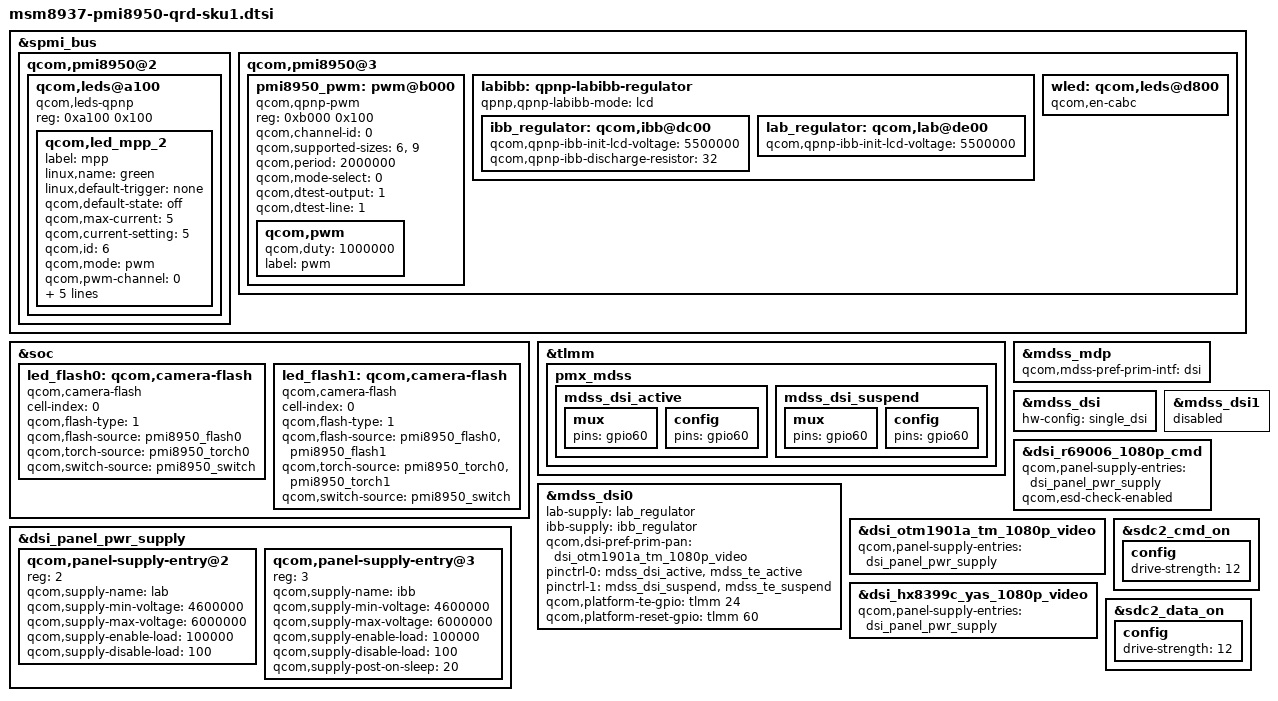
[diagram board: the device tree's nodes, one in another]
/*
 * Copyright (c) 2015-2016, The Linux Foundation. All rights reserved.
 *
 * This program is free software; you can redistribute it and/or modify
 * it under the terms of the GNU General Public License version 2 and
 * only version 2 as published by the Free Software Foundation.
 *
 * This program is distributed in the hope that it will be useful,
 * but WITHOUT ANY WARRANTY; without even the implied warranty of
 * MERCHANTABILITY or FITNESS FOR A PARTICULAR PURPOSE.  See the
 * GNU General Public License for more details.
 */

#include "msm-pmi8950.dtsi"
#include "msm8937-qrd.dtsi"
#include "msm8937-mdss-panels.dtsi"
#include "dsi-panel-otm1901a-tm-1080p-video.dtsi"

&spmi_bus {
	qcom,pmi8950@2 {
                qcom,leds@a100 {
                        compatible = "qcom,leds-qpnp";
                        reg = <0xa100 0x100>;
                        status = "okay";
                        qcom,led_mpp_2 {
                                label = "mpp";
                                linux,name = "green";
                                linux,default-trigger = "none";
                                qcom,default-state = "off";
                                qcom,max-current = <5>;
                                qcom,current-setting = <5>;
                                qcom,id = <6>;
                                qcom,mode = "pwm";
                                qcom,pwm-channel = <0>;
                                pwms = <&pmi8950_pwm 0 0>;
                                pwm-names="green";
                                qcom,source-sel = <8>;
                                qcom,pwm-us=<1000>;
                                qcom,mode-ctrl = <0x60>;
                        };
                };
        };

        qcom,pmi8950@3 {
                pmi8950_pwm: pwm@b000{
                        status = "okay";
                        compatible = "qcom,qpnp-pwm";
                        reg = <0xb000 0x100>;
                        reg-names = "qpnp-lpg-channel-base";
                        qcom,channel-id = <0>;
                        qcom,supported-sizes = <6>,<9>;
                        qcom,period = <2000000>;
                        qcom,mode-select=<0>;
                        qcom,dtest-output = <1>;
                        qcom,dtest-line = <1>;
                        #pwm-cells = <2>;
                        qcom,pwm{
                                qcom,duty = <1000000>;
                                label = "pwm";
                        };
                };
        };
};

&soc {
	led_flash0: qcom,camera-flash {
		cell-index = <0>;
		compatible = "qcom,camera-flash";
		qcom,flash-type = <1>;
		qcom,flash-source = <&pmi8950_flash0>;
		qcom,torch-source = <&pmi8950_torch0>;
		qcom,switch-source = <&pmi8950_switch>;
	};

	led_flash1: qcom,camera-flash {
		cell-index = <0>;
		compatible = "qcom,camera-flash";
		qcom,flash-type = <1>;
		qcom,flash-source = <&pmi8950_flash0 &pmi8950_flash1>;
		qcom,torch-source = <&pmi8950_torch0 &pmi8950_torch1>;
		qcom,switch-source = <&pmi8950_switch>;
	};
};

&tlmm {
	pmx_mdss: pmx_mdss {
		mdss_dsi_active: mdss_dsi_active {
			mux {
				pins = "gpio60";
			};
			config {
				pins = "gpio60";
			};
		};
		mdss_dsi_suspend: mdss_dsi_suspend {
			mux {
				pins = "gpio60";
			};
			config {
				pins = "gpio60";
			};
		};
	};

};

&mdss_mdp {
	qcom,mdss-pref-prim-intf = "dsi";
};

&mdss_dsi {
	hw-config = "single_dsi";
};

&mdss_dsi0 {
	lab-supply = <&lab_regulator>;
	ibb-supply = <&ibb_regulator>;

	qcom,dsi-pref-prim-pan = <&dsi_otm1901a_tm_1080p_video>;
	pinctrl-names = "mdss_default", "mdss_sleep";
	pinctrl-0 = <&mdss_dsi_active &mdss_te_active>;
	pinctrl-1 = <&mdss_dsi_suspend &mdss_te_suspend>;

	qcom,platform-te-gpio = <&tlmm 24 0>;
	qcom,platform-reset-gpio = <&tlmm 60 0>;
};

&mdss_dsi1 {
	status = "disabled";
};

&labibb {
	status = "ok";
	qpnp,qpnp-labibb-mode = "lcd";
};

&ibb_regulator {
	qcom,qpnp-ibb-discharge-resistor = <32>;
};

&dsi_panel_pwr_supply {
	qcom,panel-supply-entry@2 {
		reg = <2>;
		qcom,supply-name = "lab";
		qcom,supply-min-voltage = <4600000>;
		qcom,supply-max-voltage = <6000000>;
		qcom,supply-enable-load = <100000>;
		qcom,supply-disable-load = <100>;
	};

	qcom,panel-supply-entry@3 {
		reg = <3>;
		qcom,supply-name = "ibb";
		qcom,supply-min-voltage = <4600000>;
		qcom,supply-max-voltage = <6000000>;
		qcom,supply-enable-load = <100000>;
		qcom,supply-disable-load = <100>;
		qcom,supply-post-on-sleep = <20>;
	};
};

&dsi_r69006_1080p_cmd {
	qcom,panel-supply-entries = <&dsi_panel_pwr_supply>;
	qcom,esd-check-enabled;
};

&dsi_otm1901a_tm_1080p_video {
	qcom,panel-supply-entries = <&dsi_panel_pwr_supply>;
	//qcom,esd-check-enabled;
};

&dsi_hx8399c_yas_1080p_video {
	qcom,panel-supply-entries = <&dsi_panel_pwr_supply>;
	//qcom,esd-check-enabled;
};

&spmi_bus {
	qcom,pmi8950@3 {
		labibb: qpnp-labibb-regulator {
			ibb_regulator: qcom,ibb@dc00 {
				/delete-property/
					qcom,qpnp-ibb-use-default-voltage;
				qcom,qpnp-ibb-init-lcd-voltage = <5500000>;
			};

			lab_regulator: qcom,lab@de00 {
				/delete-property/
					qcom,qpnp-ibb-use-default-voltage;
				qcom,qpnp-ibb-init-lcd-voltage = <5500000>;
			};
		};
		wled: qcom,leds@d800 {
			qcom,en-cabc;
		};
	};
};

&sdc2_cmd_on {
	config {
		drive-strength = <12>;
	};
};

&sdc2_data_on {
	config {
		drive-strength = <12>;
	};
};
